# MCXA156 register map
Vendor: nxp.com; File version: 1.0
CPU: CM33 r2p0, little endian, no MPU, FPU, VTOR, 3 interrupt priority bits
Registers are 32-bit, read-write, reset 0x0 unless marked. A register's access mark holds for its fields unless they carry their own. Offsets are from the block's base; [hi:lo] are bit positions; {n}, {i} and the like mark numbered series; 'fields as' and 'values as' point back to an identical list.

## MRCC0 — MRCC
Base 0x40091000
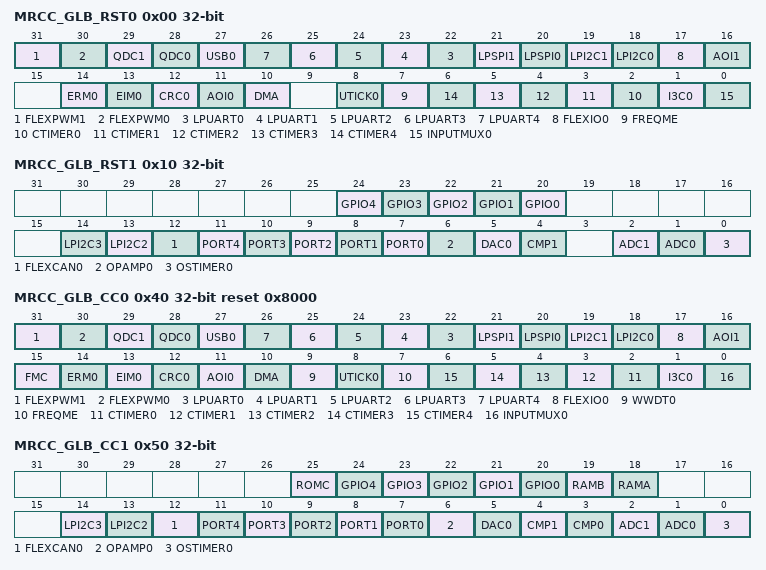
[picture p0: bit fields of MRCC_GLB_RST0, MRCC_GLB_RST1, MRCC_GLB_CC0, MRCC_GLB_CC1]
0x00 MRCC_GLB_RST0 — Peripheral Reset Control 0
  [all] fields
    0=DISABLED (Peripheral is held in reset); 1=ENABLED (Peripheral is released from reset)
  [31] FLEXPWM1
  [30] FLEXPWM0
  [29] QDC1
  [28] QDC0
  [27] USB0
  [n+22] LPUART{n} (n=0..4)
  [21] LPSPI1
  [20] LPSPI0
  [19] LPI2C1
  [18] LPI2C0
  [17] FLEXIO0
  [16] AOI1
  [14] ERM0
  [13] EIM0
  [12] CRC0
  [11] AOI0
  [10] DMA
  [8] UTICK0
  [7] FREQME
  [n+2] CTIMER{n} (n=0..4)
  [1] I3C0
  [0] INPUTMUX0
0x04 MRCC_GLB_RST0_SET wo — Peripheral Reset Control Set 0
  [31:0] DATA — Data array value, refer to corresponding position in MRCC_GLB_RSTn.
0x08 MRCC_GLB_RST0_CLR wo — Peripheral Reset Control Clear 0
  fields as MRCC_GLB_RST0_SET
0x10 MRCC_GLB_RST1 — Peripheral Reset Control 1
  [all] fields
    values as the fields of MRCC_GLB_RST0
  [n+20] GPIO{n} (n=0..4)
  [14] LPI2C3
  [13] LPI2C2
  [12] FLEXCAN0
  [n+7] PORT{n} (n=0..4)
  [6] OPAMP0
  [5] DAC0
  [4] CMP1
  [2] ADC1
  [1] ADC0
  [0] OSTIMER0
0x14 MRCC_GLB_RST1_SET wo — Peripheral Reset Control Set 1
  fields as MRCC_GLB_RST0_SET
0x18 MRCC_GLB_RST1_CLR wo — Peripheral Reset Control Clear 1
  fields as MRCC_GLB_RST0_SET
0x40 MRCC_GLB_CC0 reset 0x8000 — AHB Clock Control 0
  [all] fields
    0=DISABLED (Peripheral clock is disabled); 1=ENABLED (Peripheral clock is enabled)
  [31] FLEXPWM1
  [30] FLEXPWM0
  [29] QDC1
  [28] QDC0
  [27] USB0
  [n+22] LPUART{n} (n=0..4)
  [21] LPSPI1
  [20] LPSPI0
  [19] LPI2C1
  [18] LPI2C0
  [17] FLEXIO0
  [16] AOI1
  [15] FMC
  [14] ERM0
  [13] EIM0
  [12] CRC0
  [11] AOI0
  [10] DMA
  [9] WWDT0
  [8] UTICK0
  [7] FREQME
  [n+2] CTIMER{n} (n=0..4)
  [1] I3C0
  [0] INPUTMUX0
0x44 MRCC_GLB_CC0_SET wo reset 0x8000 — AHB Clock Control Set 0
  [31:0] DATA — Data array value, refer to corresponding position in MRCC_GLB_CCn.
0x48 MRCC_GLB_CC0_CLR wo reset 0x8000 — AHB Clock Control Clear 0
  fields as MRCC_GLB_CC0_SET
0x50 MRCC_GLB_CC1 — AHB Clock Control 1
  [all] fields
    values as the fields of MRCC_GLB_CC0
  [25] ROMC
  [n+20] GPIO{n} (n=0..4)
  [19] RAMB
  [18] RAMA
  [14] LPI2C3
  [13] LPI2C2
  [12] FLEXCAN0
  [n+7] PORT{n} (n=0..4)
  [6] OPAMP0
  [5] DAC0
  [4] CMP1
  [3] CMP0
  [2] ADC1
  [1] ADC0
  [0] OSTIMER0
0x54 MRCC_GLB_CC1_SET wo — AHB Clock Control Set 1
  fields as MRCC_GLB_CC0_SET
0x58 MRCC_GLB_CC1_CLR wo — AHB Clock Control Clear 1
  fields as MRCC_GLB_CC0_SET
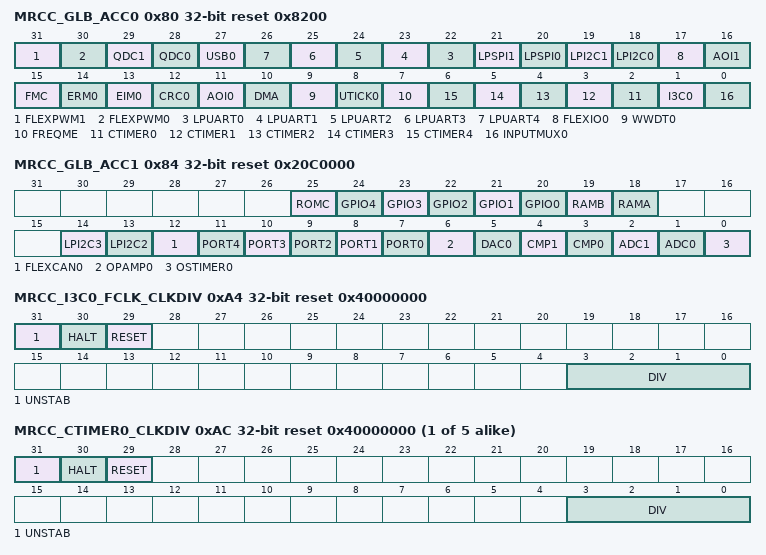
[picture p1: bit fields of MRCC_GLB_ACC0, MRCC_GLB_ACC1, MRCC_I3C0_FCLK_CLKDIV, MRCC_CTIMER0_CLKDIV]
0x80 MRCC_GLB_ACC0 reset 0x8200 — Control Automatic Clock Gating 0
  [all] fields
    0=DISABLED (Automatic clock gating is disabled); 1=ENABLED (Automatic clock gating is enabled)
  [31] FLEXPWM1
  [30] FLEXPWM0
  [29] QDC1
  [28] QDC0
  [27] USB0
  [n+22] LPUART{n} (n=0..4)
  [21] LPSPI1
  [20] LPSPI0
  [19] LPI2C1
  [18] LPI2C0
  [17] FLEXIO0
  [16] AOI1
  [15] FMC
  [14] ERM0
  [13] EIM0
  [12] CRC0
  [11] AOI0
  [10] DMA
  [9] WWDT0
  [8] UTICK0
  [7] FREQME
  [n+2] CTIMER{n} (n=0..4)
  [1] I3C0
  [0] INPUTMUX0
0x84 MRCC_GLB_ACC1 reset 0x20C0000 — Control Automatic Clock Gating 1
  [all] fields
    values as the fields of MRCC_GLB_ACC0
  [25] ROMC
  [n+20] GPIO{n} (n=0..4)
  [19] RAMB
  [18] RAMA
  [14] LPI2C3
  [13] LPI2C2
  [12] FLEXCAN0
  [n+7] PORT{n} (n=0..4)
  [6] OPAMP0
  [5] DAC0
  [4] CMP1
  [3] CMP0
  [2] ADC1
  [1] ADC0
  [0] OSTIMER0
0xA0 MRCC_I3C0_FCLK_CLKSEL reset 0x7 — I3C0_FCLK clock selection control
  [2:0] MUX — Functional Clock Mux Select
    0=clkroot_func_0 (FRO_12M); 2=clkroot_func_2 (FRO_HF_DIV); 3=clkroot_func_3 (CLK_IN); 5=clkroot_func_5 (CLK_1M)
0xA4 MRCC_I3C0_FCLK_CLKDIV reset 0x40000000 — I3C0_FCLK clock divider control
  [31] UNSTAB ro — Divider status flag
    0=ON (Divider clock is stable); 1=OFF (Clock frequency isn't stable)
  [30] HALT — Halt divider counter
    0=ON (Divider clock is running); 1=OFF (Divider clock is stopped)
  [29] RESET wo — Reset divider counter
    0=ON (Divider isn't reset); 1=OFF (Divider is reset)
  [3:0] DIV — Functional Clock Divider
{0xA8+8i} MRCC_CTIMER{i}_CLKSEL reset 0x7 (i=0..4) — CTIMER{i} clock selection control
  [2:0] MUX — Functional Clock Mux Select
    0=clkroot_func_0 (FRO_12M); 1=clkroot_func_1 (FRO_HF_GATED); 3=clkroot_func_3 (CLK_IN); 4=clkroot_func_4 (CLK_16K); 5=clkroot_func_5 (CLK_1M)
{0xAC+8i} MRCC_CTIMER{i}_CLKDIV reset 0x40000000 (i=0..4) — CTIMER{i} clock divider control
  fields as MRCC_I3C0_FCLK_CLKDIV
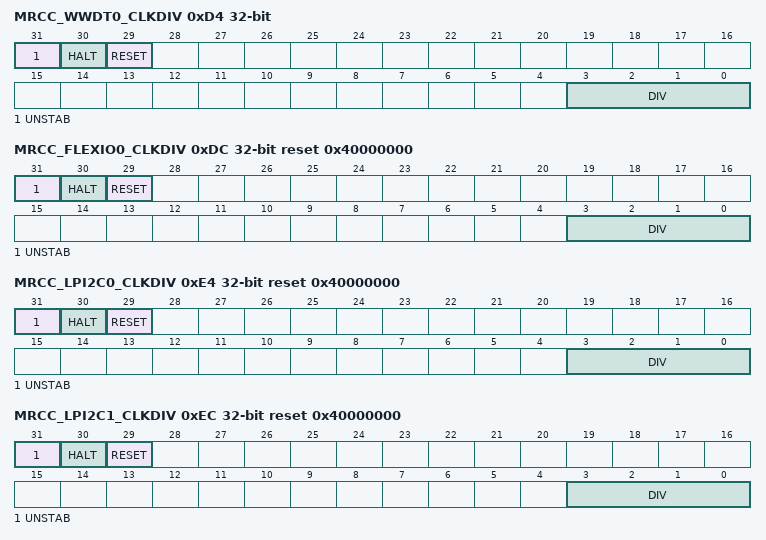
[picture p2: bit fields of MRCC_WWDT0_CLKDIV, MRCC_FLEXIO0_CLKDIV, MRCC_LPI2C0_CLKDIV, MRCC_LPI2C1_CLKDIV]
0xD4 MRCC_WWDT0_CLKDIV — WWDT0 clock divider control
  fields as MRCC_I3C0_FCLK_CLKDIV
0xD8 MRCC_FLEXIO0_CLKSEL reset 0x7 — FLEXIO0 clock selection control
  [2:0] MUX — Functional Clock Mux Select
    0=clkroot_func_0 (FRO_12M); 1=clkroot_func_1 (FRO_HF_GATED); 3=clkroot_func_3 (CLK_IN); 5=clkroot_func_5 (CLK_1M)
0xDC MRCC_FLEXIO0_CLKDIV reset 0x40000000 — FLEXIO0 clock divider control
  fields as MRCC_I3C0_FCLK_CLKDIV
0xE0 MRCC_LPI2C0_CLKSEL reset 0x7 — LPI2C0 clock selection control
  fields as MRCC_I3C0_FCLK_CLKSEL
0xE4 MRCC_LPI2C0_CLKDIV reset 0x40000000 — LPI2C0 clock divider control
  fields as MRCC_I3C0_FCLK_CLKDIV
0xE8 MRCC_LPI2C1_CLKSEL reset 0x7 — LPI2C1 clock selection control
  fields as MRCC_I3C0_FCLK_CLKSEL
0xEC MRCC_LPI2C1_CLKDIV reset 0x40000000 — LPI2C1 clock divider control
  fields as MRCC_I3C0_FCLK_CLKDIV
0xF0 MRCC_LPSPI0_CLKSEL reset 0x7 — LPSPI0 clock selection control
  fields as MRCC_I3C0_FCLK_CLKSEL
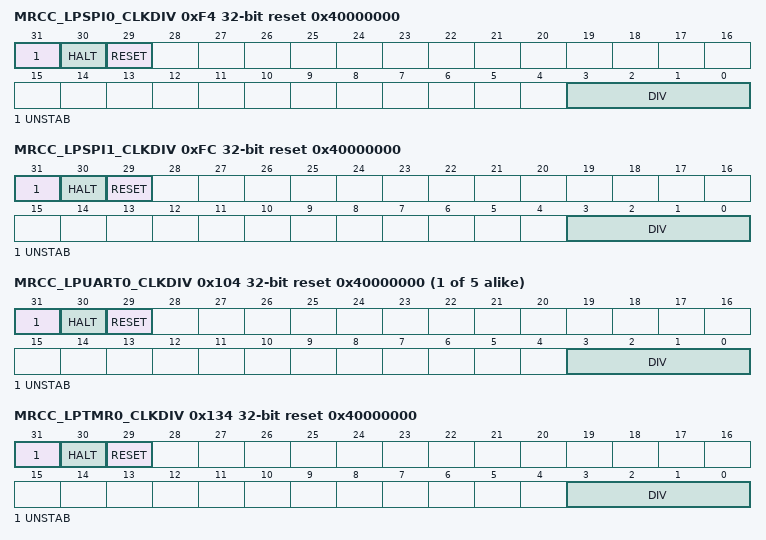
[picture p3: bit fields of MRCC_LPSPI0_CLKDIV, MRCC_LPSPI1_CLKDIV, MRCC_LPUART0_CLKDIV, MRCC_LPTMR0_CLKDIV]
0xF4 MRCC_LPSPI0_CLKDIV reset 0x40000000 — LPSPI0 clock divider control
  fields as MRCC_I3C0_FCLK_CLKDIV
0xF8 MRCC_LPSPI1_CLKSEL reset 0x7 — LPSPI1 clock selection control
  fields as MRCC_I3C0_FCLK_CLKSEL
0xFC MRCC_LPSPI1_CLKDIV reset 0x40000000 — LPSPI1 clock divider control
  fields as MRCC_I3C0_FCLK_CLKDIV
{0x100+8i} MRCC_LPUART{i}_CLKSEL reset 0x7 (i=0..4) — LPUART{i} clock selection control
  [2:0] MUX — Functional Clock Mux Select
    0=clkroot_func_0 (FRO_12M); 2=clkroot_func_2 (FRO_HF_DIV); 3=clkroot_func_3 (CLK_IN); 4=clkroot_func_4 (CLK_16K); 5=clkroot_func_5 (CLK_1M)
{0x104+8i} MRCC_LPUART{i}_CLKDIV reset 0x40000000 (i=0..4) — LPUART{i} clock divider control
  fields as MRCC_I3C0_FCLK_CLKDIV
0x128 MRCC_USB0_CLKSEL reset 0x3 — USB0 clock selection control
  [1:0] MUX — Functional Clock Mux Select
    1=scg_scg_firc_48mhz_clk (CLK_48M); 2=clkroot_sosc (CLK_IN)
0x130 MRCC_LPTMR0_CLKSEL reset 0x7 — LPTMR0 clock selection control
  fields as MRCC_I3C0_FCLK_CLKSEL
0x134 MRCC_LPTMR0_CLKDIV reset 0x40000000 — LPTMR0 clock divider control
  fields as MRCC_I3C0_FCLK_CLKDIV
0x138 MRCC_OSTIMER0_CLKSEL reset 0x3 — OSTIMER0 clock selection control
  [1:0] MUX — Functional Clock Mux Select
    0=clkroot_16k (CLK_16K); 2=clkroot_1m (CLK_1M)
0x140 MRCC_ADC0_CLKSEL reset 0x7 — ADC0 clock selection control
  fields as MRCC_FLEXIO0_CLKSEL
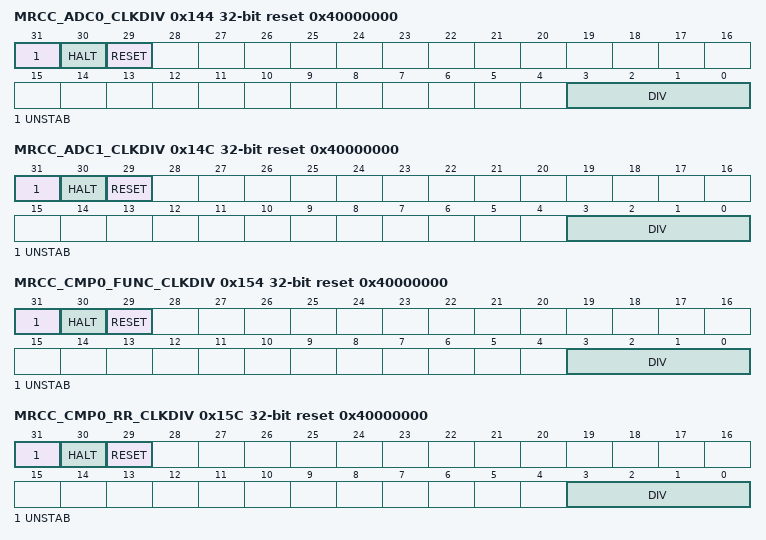
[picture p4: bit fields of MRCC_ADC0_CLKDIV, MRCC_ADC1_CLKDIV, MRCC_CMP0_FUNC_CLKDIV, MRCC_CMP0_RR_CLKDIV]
0x144 MRCC_ADC0_CLKDIV reset 0x40000000 — ADC0 clock divider control
  fields as MRCC_I3C0_FCLK_CLKDIV
0x148 MRCC_ADC1_CLKSEL reset 0x7 — ADC1 clock selection control
  fields as MRCC_FLEXIO0_CLKSEL
0x14C MRCC_ADC1_CLKDIV reset 0x40000000 — ADC1 clock divider control
  fields as MRCC_I3C0_FCLK_CLKDIV
0x154 MRCC_CMP0_FUNC_CLKDIV reset 0x40000000 — CMP0_FUNC clock divider control
  fields as MRCC_I3C0_FCLK_CLKDIV
0x158 MRCC_CMP0_RR_CLKSEL reset 0x7 — CMP0_RR clock selection control
  fields as MRCC_I3C0_FCLK_CLKSEL
0x15C MRCC_CMP0_RR_CLKDIV reset 0x40000000 — CMP0_RR clock divider control
  fields as MRCC_I3C0_FCLK_CLKDIV
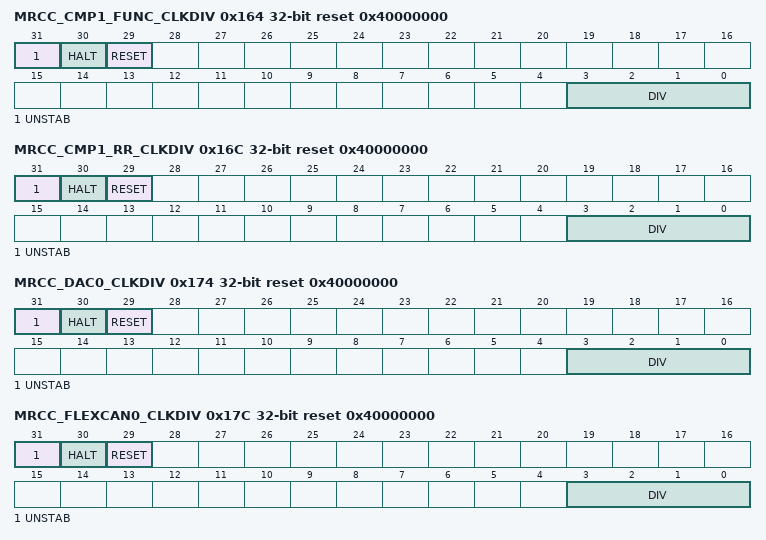
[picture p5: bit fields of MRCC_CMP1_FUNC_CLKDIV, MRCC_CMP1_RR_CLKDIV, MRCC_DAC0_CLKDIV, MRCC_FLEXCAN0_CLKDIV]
0x164 MRCC_CMP1_FUNC_CLKDIV reset 0x40000000 — CMP1_FUNC clock divider control
  fields as MRCC_I3C0_FCLK_CLKDIV
0x168 MRCC_CMP1_RR_CLKSEL reset 0x7 — CMP1_RR clock selection control
  fields as MRCC_I3C0_FCLK_CLKSEL
0x16C MRCC_CMP1_RR_CLKDIV reset 0x40000000 — CMP1_RR clock divider control
  fields as MRCC_I3C0_FCLK_CLKDIV
0x170 MRCC_DAC0_CLKSEL reset 0x7 — DAC0 clock selection control
  fields as MRCC_I3C0_FCLK_CLKSEL
0x174 MRCC_DAC0_CLKDIV reset 0x40000000 — DAC0 clock divider control
  fields as MRCC_I3C0_FCLK_CLKDIV
0x178 MRCC_FLEXCAN0_CLKSEL reset 0x7 — FLEXCAN0 clock selection control
  [2:0] MUX — Functional Clock Mux Select
    2=clkroot_func_2 (FRO_HF_DIV); 3=clkroot_func_3 (CLK_IN)
0x17C MRCC_FLEXCAN0_CLKDIV reset 0x40000000 — FLEXCAN0 clock divider control
  fields as MRCC_I3C0_FCLK_CLKDIV
0x180 MRCC_LPI2C2_CLKSEL reset 0x7 — LPI2C2 clock selection control
  fields as MRCC_I3C0_FCLK_CLKSEL
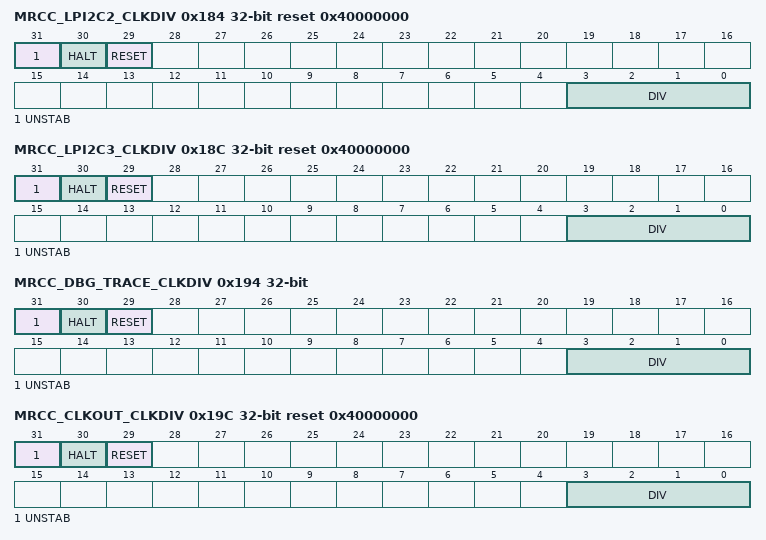
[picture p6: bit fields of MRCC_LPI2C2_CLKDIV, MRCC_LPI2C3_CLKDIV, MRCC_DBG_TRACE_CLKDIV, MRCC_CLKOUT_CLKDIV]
0x184 MRCC_LPI2C2_CLKDIV reset 0x40000000 — LPI2C2 clock divider control
  fields as MRCC_I3C0_FCLK_CLKDIV
0x188 MRCC_LPI2C3_CLKSEL reset 0x7 — LPI2C3 clock selection control
  fields as MRCC_I3C0_FCLK_CLKSEL
0x18C MRCC_LPI2C3_CLKDIV reset 0x40000000 — LPI2C3 clock divider control
  fields as MRCC_I3C0_FCLK_CLKDIV
0x190 MRCC_DBG_TRACE_CLKSEL — DBG_TRACE clock selection control
  [1:0] MUX — Functional Clock Mux Select
    0=clkroot_cpu (CPU_CLK); 1=clkroot_1m (CLK_1M); 2=clkroot_16k (CLK_16K)
0x194 MRCC_DBG_TRACE_CLKDIV — DBG_TRACE clock divider control
  fields as MRCC_I3C0_FCLK_CLKDIV
0x198 MRCC_CLKOUT_CLKSEL reset 0x7 — CLKOUT clock selection control
  [2:0] MUX — Functional Clock Mux Select
    0=clkroot_12m (FRO_12M); 1=clkroot_firc_div (FRO_HF_DIV); 2=clkroot_sosc (CLK_IN); 3=clkroot_16k (CLK_16K); 6=clkroot_slow (SLOW_CLK)
0x19C MRCC_CLKOUT_CLKDIV reset 0x40000000 — CLKOUT clock divider control
  fields as MRCC_I3C0_FCLK_CLKDIV
0x1A0 MRCC_SYSTICK_CLKSEL reset 0x3 — SYSTICK clock selection control
  fields as MRCC_DBG_TRACE_CLKSEL
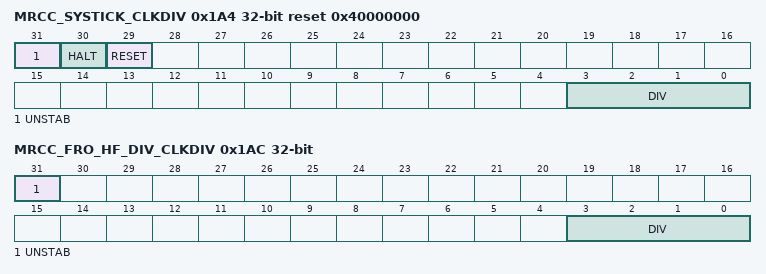
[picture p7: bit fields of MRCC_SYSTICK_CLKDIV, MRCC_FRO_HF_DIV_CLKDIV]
0x1A4 MRCC_SYSTICK_CLKDIV reset 0x40000000 — SYSTICK clock divider control
  fields as MRCC_I3C0_FCLK_CLKDIV
0x1AC MRCC_FRO_HF_DIV_CLKDIV — FRO_HF_DIV clock divider control
  [31] UNSTAB ro — Divider status flag
    values as MRCC_I3C0_FCLK_CLKDIV.UNSTAB
  [3:0] DIV — Functional Clock Divider
